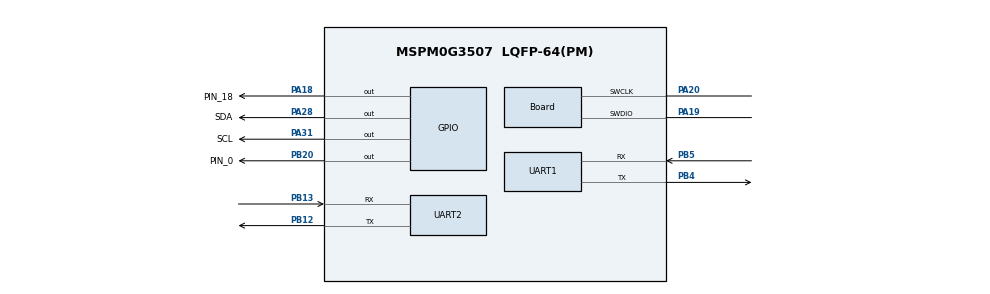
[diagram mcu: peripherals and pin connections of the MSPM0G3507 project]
/**
 * These arguments were used when this file was generated. They will be automatically applied on subsequent loads
 * via the GUI or CLI. Run CLI with '--help' for additional information on how to override these arguments.
 * @cliArgs --device "MSPM0G350X" --part "Default" --package "LQFP-64(PM)" --product "mspm0_sdk@2.04.00.06"
 * @v2CliArgs --device "MSPM0G3507" --package "LQFP-64(PM)" --product "mspm0_sdk@2.04.00.06"
 * @versions {"tool":"1.22.0+3893"}
 */

/**
 * Import the modules used in this configuration.
 */
const GPIO          = scripting.addModule("/ti/driverlib/GPIO", {}, false);
const GPIO1         = GPIO.addInstance();
const GPIO2         = GPIO.addInstance();
const GPIO3         = GPIO.addInstance();
const I2C           = scripting.addModule("/ti/driverlib/I2C", {}, false);
const I2C1          = I2C.addInstance();
const SYSCTL        = scripting.addModule("/ti/driverlib/SYSCTL");
const SYSTICK       = scripting.addModule("/ti/driverlib/SYSTICK");
const UART          = scripting.addModule("/ti/driverlib/UART", {}, false);
const UART1         = UART.addInstance();
const UART2         = UART.addInstance();
const ProjectConfig = scripting.addModule("/ti/project_config/ProjectConfig");

/**
 * Write custom configuration values to the imported modules.
 */
const divider6       = system.clockTree["PLL_CLK2X_DIV"];
divider6.divideValue = 4;

const divider7       = system.clockTree["PLL_PDIV"];
divider7.divideValue = 2;

const divider9       = system.clockTree["UDIV"];
divider9.divideValue = 2;

const multiplier2         = system.clockTree["PLL_QDIV"];
multiplier2.multiplyValue = 10;

const mux8       = system.clockTree["HSCLKMUX"];
mux8.inputSelect = "HSCLKMUX_SYSPLL2X";

GPIO1.$name                          = "BSL";
GPIO1.associatedPins[0].$name        = "PIN_18";
GPIO1.associatedPins[0].assignedPin  = "18";
GPIO1.associatedPins[0].assignedPort = "PORTA";
GPIO1.associatedPins[0].pin.$assign  = "PA18";

const Board                       = scripting.addModule("/ti/driverlib/Board", {}, false);
Board.peripheral.$assign          = "DEBUGSS";
Board.peripheral.swclkPin.$assign = "PA20";
Board.peripheral.swdioPin.$assign = "PA19";

GPIO2.$name                              = "I2C";
GPIO2.associatedPins.create(2);
GPIO2.associatedPins[0].$name            = "SDA";
GPIO2.associatedPins[0].assignedPin      = "28";
GPIO2.associatedPins[0].initialValue     = "SET";
GPIO2.associatedPins[0].pin.$assign      = "PA28";
GPIO2.associatedPins[1].$name            = "SCL";
GPIO2.associatedPins[1].internalResistor = "PULL_UP";
GPIO2.associatedPins[1].assignedPort     = "PORTA";
GPIO2.associatedPins[1].assignedPin      = "31";
GPIO2.associatedPins[1].initialValue     = "SET";
GPIO2.associatedPins[1].pin.$assign      = "PA31";

GPIO3.$name                          = "test";
GPIO3.associatedPins[0].$name        = "PIN_0";
GPIO3.associatedPins[0].initialValue = "SET";
GPIO3.associatedPins[0].pin.$assign  = "PB20";

I2C1.$name                             = "JY61P";
I2C1.basicEnableController             = true;
I2C1.sdaPinConfig.hideOutputInversion  = scripting.forceWrite(false);
I2C1.sdaPinConfig.onlyInternalResistor = scripting.forceWrite(false);
I2C1.sdaPinConfig.passedPeripheralType = scripting.forceWrite("Digital");
I2C1.sdaPinConfig.$name                = "ti_driverlib_gpio_GPIOPinGeneric2";
I2C1.sclPinConfig.hideOutputInversion  = scripting.forceWrite(false);
I2C1.sclPinConfig.onlyInternalResistor = scripting.forceWrite(false);
I2C1.sclPinConfig.passedPeripheralType = scripting.forceWrite("Digital");
I2C1.sclPinConfig.$name                = "ti_driverlib_gpio_GPIOPinGeneric3";

SYSCTL.forceDefaultClkConfig = true;
SYSCTL.clockTreeEn           = true;
scripting.suppress("For best practices when the CPUCLK is running at 32MHz and above, clear the flash status bit using DL_FlashCTL_executeClearStatus\\(\\) before executing any flash operation\\. Otherwise there may be false positives\\.", SYSCTL);

SYSTICK.periodEnable      = true;
SYSTICK.interruptEnable   = true;
SYSTICK.systickEnable     = true;
SYSTICK.interruptPriority = "0";
SYSTICK.period            = 80000;

UART1.$name                            = "BLE05";
UART1.targetBaudRate                   = 115200;
UART1.uartClkDiv                       = "3";
UART1.enabledInterrupts                = ["RX"];
UART1.enableFIFO                       = true;
UART1.peripheral.$assign               = "UART1";
UART1.peripheral.rxPin.$assign         = "PB5";
UART1.peripheral.txPin.$assign         = "PB4";
UART1.txPinConfig.direction            = scripting.forceWrite("OUTPUT");
UART1.txPinConfig.hideOutputInversion  = scripting.forceWrite(false);
UART1.txPinConfig.onlyInternalResistor = scripting.forceWrite(false);
UART1.txPinConfig.passedPeripheralType = scripting.forceWrite("Digital");
UART1.txPinConfig.$name                = "ti_driverlib_gpio_GPIOPinGeneric0";
UART1.rxPinConfig.hideOutputInversion  = scripting.forceWrite(false);
UART1.rxPinConfig.onlyInternalResistor = scripting.forceWrite(false);
UART1.rxPinConfig.passedPeripheralType = scripting.forceWrite("Digital");
UART1.rxPinConfig.$name                = "ti_driverlib_gpio_GPIOPinGeneric1";

UART2.$name                            = "OPENMV";
UART2.targetBaudRate                   = 115200;
UART2.enabledInterrupts                = ["RX"];
UART2.enableFIFO                       = true;
UART2.peripheral.$assign               = "UART3";
UART2.peripheral.rxPin.$assign         = "PB13";
UART2.peripheral.txPin.$assign         = "PB12";
UART2.txPinConfig.$name                = "ti_driverlib_gpio_GPIOPinGeneric4";
UART2.txPinConfig.direction            = scripting.forceWrite("OUTPUT");
UART2.txPinConfig.hideOutputInversion  = scripting.forceWrite(false);
UART2.txPinConfig.onlyInternalResistor = scripting.forceWrite(false);
UART2.txPinConfig.passedPeripheralType = scripting.forceWrite("Digital");
UART2.rxPinConfig.$name                = "ti_driverlib_gpio_GPIOPinGeneric5";
UART2.rxPinConfig.hideOutputInversion  = scripting.forceWrite(false);
UART2.rxPinConfig.onlyInternalResistor = scripting.forceWrite(false);
UART2.rxPinConfig.passedPeripheralType = scripting.forceWrite("Digital");

ProjectConfig.migrationCondition = true;
ProjectConfig.genLibIQVersion    = "MATHACL";

/**
 * Pinmux solution for unlocked pins/peripherals. This ensures that minor changes to the automatic solver in a future
 * version of the tool will not impact the pinmux you originally saw.  These lines can be completely deleted in order to
 * re-solve from scratch.
 */
I2C1.peripheral.$suggestSolution        = "I2C0";
I2C1.peripheral.sdaPin.$suggestSolution = "PA0";
I2C1.peripheral.sclPin.$suggestSolution = "PA1";
